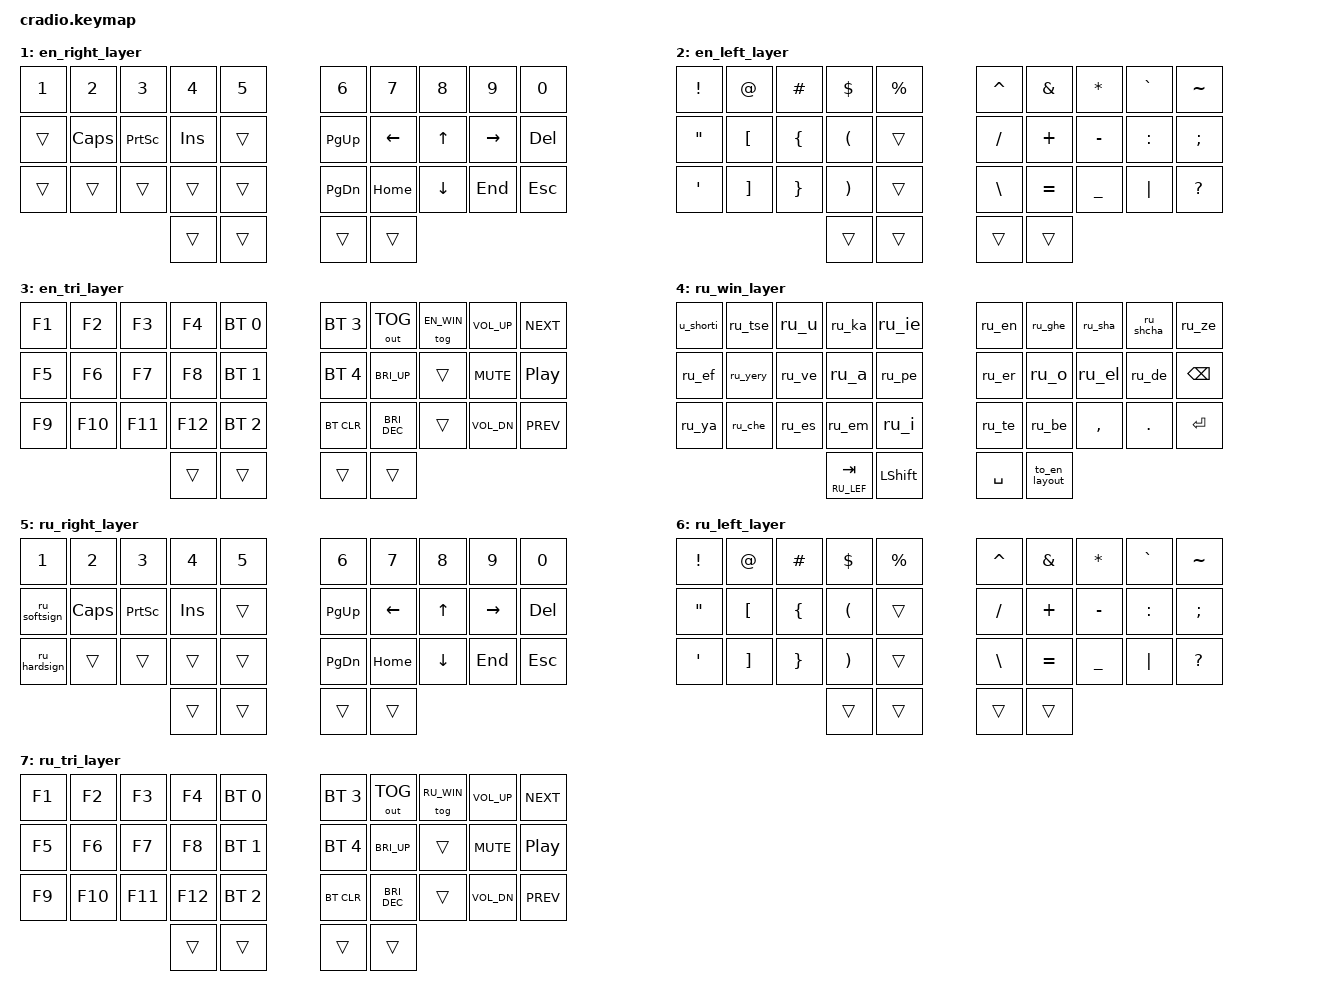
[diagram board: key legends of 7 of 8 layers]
// Copyright (c) 2022 The ZMK Contributors
// SPDX-License-Identifier: MIT

#include <behaviors.dtsi>
#include <dt-bindings/zmk/keys.h>
#include <dt-bindings/zmk/bt.h>
#include <dt-bindings/zmk/outputs.h>

// Home row mods macro
#define HRML(k2,k3,k4) &ht LALT k2  &ht LCTRL k3  &ht LGUI k4
#define HRMR(k1,k2,k3) &ht RGUI k1  &ht RCTRL k2  &ht RALT k3
#define WHRML(k2,k3,k4) &ht LALT k2  &ht LGUI k3  &ht LCTRL k4
#define WHRMR(k1,k2,k3) &ht RCTRL k1  &ht RGUI k2  &ht RALT k3

#define EN_WIN 0
#define EN_RIG 1
#define EN_LEF 2
#define EN_TRI 3
#define RU_WIN 4
#define RU_RIG 5
#define RU_LEF 6
#define RU_TRI 7

/ {
    behaviors {
        ht: hold_tap {
            label = "hold_tap";
            compatible = "zmk,behavior-hold-tap";
            #binding-cells = <2>;
            flavor = "tap-preferred";
            tapping-term-ms = <220>;
            quick-tap-ms = <150>;
            global-quick-tap;
            bindings = <&kp>, <&kp>;
        };

        // Макросы для русских букв через Alt+Unicode
        ru_shorti: ru_shorti { compatible = "zmk,behavior-macro"; label = "RU_SHORTI"; #binding-cells = <0>; 
            bindings = <&macro_press &kp LALT>, <&macro_tap &kp KP_N0 &kp KP_N4 &kp KP_N0 &kp KP_N9>, <&macro_release &kp LALT>; }; // Й
        ru_tse: ru_tse { compatible = "zmk,behavior-macro"; label = "RU_TSE"; #binding-cells = <0>; 
            bindings = <&macro_press &kp LALT>, <&macro_tap &kp KP_N0 &kp KP_N4 &kp KP_N2 &kp KP_N6>, <&macro_release &kp LALT>; }; // Ц
        ru_u: ru_u { compatible = "zmk,behavior-macro"; label = "RU_U"; #binding-cells = <0>; 
            bindings = <&macro_press &kp LALT>, <&macro_tap &kp KP_N0 &kp KP_N4 &kp KP_N2 &kp KP_N3>, <&macro_release &kp LALT>; }; // У
        ru_ka: ru_ka { compatible = "zmk,behavior-macro"; label = "RU_KA"; #binding-cells = <0>; 
            bindings = <&macro_press &kp LALT>, <&macro_tap &kp KP_N0 &kp KP_N4 &kp KP_N2 &kp KP_N0>, <&macro_release &kp LALT>; }; // К
        ru_ie: ru_ie { compatible = "zmk,behavior-macro"; label = "RU_IE"; #binding-cells = <0>; 
            bindings = <&macro_press &kp LALT>, <&macro_tap &kp KP_N0 &kp KP_N4 &kp KP_N2 &kp KP_N5>, <&macro_release &kp LALT>; }; // Е
        ru_en: ru_en { compatible = "zmk,behavior-macro"; label = "RU_EN"; #binding-cells = <0>; 
            bindings = <&macro_press &kp LALT>, <&macro_tap &kp KP_N0 &kp KP_N4 &kp KP_N2 &kp KP_N1>, <&macro_release &kp LALT>; }; // Н
        ru_ghe: ru_ghe { compatible = "zmk,behavior-macro"; label = "RU_GHE"; #binding-cells = <0>; 
            bindings = <&macro_press &kp LALT>, <&macro_tap &kp KP_N0 &kp KP_N4 &kp KP_N1 &kp KP_N7>, <&macro_release &kp LALT>; }; // Г
        ru_sha: ru_sha { compatible = "zmk,behavior-macro"; label = "RU_SHA"; #binding-cells = <0>; 
            bindings = <&macro_press &kp LALT>, <&macro_tap &kp KP_N0 &kp KP_N4 &kp KP_N2 &kp KP_N8>, <&macro_release &kp LALT>; }; // Ш
        ru_shcha: ru_shcha { compatible = "zmk,behavior-macro"; label = "RU_SHCHA"; #binding-cells = <0>; 
            bindings = <&macro_press &kp LALT>, <&macro_tap &kp KP_N0 &kp KP_N4 &kp KP_N2 &kp KP_N9>, <&macro_release &kp LALT>; }; // Щ
        ru_ze: ru_ze { compatible = "zmk,behavior-macro"; label = "RU_ZE"; #binding-cells = <0>; 
            bindings = <&macro_press &kp LALT>, <&macro_tap &kp KP_N0 &kp KP_N4 &kp KP_N1 &kp KP_N7>, <&macro_release &kp LALT>; }; // З
        ru_ha: ru_ha { compatible = "zmk,behavior-macro"; label = "RU_HA"; #binding-cells = <0>; 
            bindings = <&macro_press &kp LALT>, <&macro_tap &kp KP_N0 &kp KP_N4 &kp KP_N2 &kp KP_N5>, <&macro_release &kp LALT>; }; // Х
        ru_hardsign: ru_hardsign { compatible = "zmk,behavior-macro"; label = "RU_HARDSIGN"; #binding-cells = <0>; 
            bindings = <&macro_press &kp LALT>, <&macro_tap &kp KP_N0 &kp KP_N4 &kp KP_N2 &kp KP_N2>, <&macro_release &kp LALT>; }; // Ъ
        ru_ef: ru_ef { compatible = "zmk,behavior-macro"; label = "RU_EF"; #binding-cells = <0>; 
            bindings = <&macro_press &kp LALT>, <&macro_tap &kp KP_N0 &kp KP_N4 &kp KP_N2 &kp KP_N4>, <&macro_release &kp LALT>; }; // Ф
        ru_yery: ru_yery { compatible = "zmk,behavior-macro"; label = "RU_YERY"; #binding-cells = <0>; 
            bindings = <&macro_press &kp LALT>, <&macro_tap &kp KP_N0 &kp KP_N4 &kp KP_N2 &kp KP_N7>, <&macro_release &kp LALT>; }; // Ы
        ru_ve: ru_ve { compatible = "zmk,behavior-macro"; label = "RU_VE"; #binding-cells = <0>; 
            bindings = <&macro_press &kp LALT>, <&macro_tap &kp KP_N0 &kp KP_N4 &kp KP_N2 &kp KP_N2>, <&macro_release &kp LALT>; }; // В
        ru_a: ru_a { compatible = "zmk,behavior-macro"; label = "RU_A"; #binding-cells = <0>; 
            bindings = <&macro_press &kp LALT>, <&macro_tap &kp KP_N0 &kp KP_N4 &kp KP_N1 &kp KP_N0>, <&macro_release &kp LALT>; }; // А
        ru_pe: ru_pe { compatible = "zmk,behavior-macro"; label = "RU_PE"; #binding-cells = <0>; 
            bindings = <&macro_press &kp LALT>, <&macro_tap &kp KP_N0 &kp KP_N4 &kp KP_N1 &kp KP_N7>, <&macro_release &kp LALT>; }; // П
        ru_er: ru_er { compatible = "zmk,behavior-macro"; label = "RU_ER"; #binding-cells = <0>; 
            bindings = <&macro_press &kp LALT>, <&macro_tap &kp KP_N0 &kp KP_N4 &kp KP_N2 &kp KP_N0>, <&macro_release &kp LALT>; }; // Р
        ru_o: ru_o { compatible = "zmk,behavior-macro"; label = "RU_O"; #binding-cells = <0>; 
            bindings = <&macro_press &kp LALT>, <&macro_tap &kp KP_N0 &kp KP_N4 &kp KP_N1 &kp KP_N5>, <&macro_release &kp LALT>; }; // О
        ru_el: ru_el { compatible = "zmk,behavior-macro"; label = "RU_EL"; #binding-cells = <0>; 
            bindings = <&macro_press &kp LALT>, <&macro_tap &kp KP_N0 &kp KP_N4 &kp KP_N1 &kp KP_N2>, <&macro_release &kp LALT>; }; // Л
        ru_de: ru_de { compatible = "zmk,behavior-macro"; label = "RU_DE"; #binding-cells = <0>; 
            bindings = <&macro_press &kp LALT>, <&macro_tap &kp KP_N0 &kp KP_N4 &kp KP_N1 &kp KP_N4>, <&macro_release &kp LALT>; }; // Д
        ru_zhe: ru_zhe { compatible = "zmk,behavior-macro"; label = "RU_ZHE"; #binding-cells = <0>; 
            bindings = <&macro_press &kp LALT>, <&macro_tap &kp KP_N0 &kp KP_N4 &kp KP_N1 &kp KP_N6>, <&macro_release &kp LALT>; }; // Ж
        ru_e: ru_e { compatible = "zmk,behavior-macro"; label = "RU_E"; #binding-cells = <0>; 
            bindings = <&macro_press &kp LALT>, <&macro_tap &kp KP_N0 &kp KP_N4 &kp KP_N2 &kp KP_N3>, <&macro_release &kp LALT>; }; // Э
        ru_ya: ru_ya { compatible = "zmk,behavior-macro"; label = "RU_YA"; #binding-cells = <0>; 
            bindings = <&macro_press &kp LALT>, <&macro_tap &kp KP_N0 &kp KP_N4 &kp KP_N2 &kp KP_N7>, <&macro_release &kp LALT>; }; // Я
        ru_che: ru_che { compatible = "zmk,behavior-macro"; label = "RU_CHE"; #binding-cells = <0>; 
            bindings = <&macro_press &kp LALT>, <&macro_tap &kp KP_N0 &kp KP_N4 &kp KP_N2 &kp KP_N5>, <&macro_release &kp LALT>; }; // Ч
        ru_es: ru_es { compatible = "zmk,behavior-macro"; label = "RU_ES"; #binding-cells = <0>; 
            bindings = <&macro_press &kp LALT>, <&macro_tap &kp KP_N0 &kp KP_N4 &kp KP_N2 &kp KP_N1>, <&macro_release &kp LALT>; }; // С
        ru_em: ru_em { compatible = "zmk,behavior-macro"; label = "RU_EM"; #binding-cells = <0>; 
            bindings = <&macro_press &kp LALT>, <&macro_tap &kp KP_N0 &kp KP_N4 &kp KP_N2 &kp KP_N0>, <&macro_release &kp LALT>; }; // М
        ru_i: ru_i { compatible = "zmk,behavior-macro"; label = "RU_I"; #binding-cells = <0>; 
            bindings = <&macro_press &kp LALT>, <&macro_tap &kp KP_N0 &kp KP_N4 &kp KP_N1 &kp KP_N8>, <&macro_release &kp LALT>; }; // И
        ru_te: ru_te { compatible = "zmk,behavior-macro"; label = "RU_TE"; #binding-cells = <0>; 
            bindings = <&macro_press &kp LALT>, <&macro_tap &kp KP_N0 &kp KP_N4 &kp KP_N2 &kp KP_N2>, <&macro_release &kp LALT>; }; // Т
        ru_softsign: ru_softsign { compatible = "zmk,behavior-macro"; label = "RU_SOFTSIGN"; #binding-cells = <0>; 
            bindings = <&macro_press &kp LALT>, <&macro_tap &kp KP_N0 &kp KP_N4 &kp KP_N2 &kp KP_N6>, <&macro_release &kp LALT>; }; // Ь
        ru_be: ru_be { compatible = "zmk,behavior-macro"; label = "RU_BE"; #binding-cells = <0>; 
            bindings = <&macro_press &kp LALT>, <&macro_tap &kp KP_N0 &kp KP_N4 &kp KP_N1 &kp KP_N1>, <&macro_release &kp LALT>; }; // Б
        ru_yu: ru_yu { compatible = "zmk,behavior-macro"; label = "RU_YU"; #binding-cells = <0>; 
            bindings = <&macro_press &kp LALT>, <&macro_tap &kp KP_N0 &kp KP_N4 &kp KP_N2 &kp KP_N0>, <&macro_release &kp LALT>; }; // Ю

        // Макрос для переключения раскладки Win11 (LShift+LCtrl)
        win_ru_switch: win_ru_switch {
            compatible = "zmk,behavior-macro";
            label = "WIN_RU_SWITCH";
            #binding-cells = <0>;
            bindings = <&kp LSHIFT>, <&kp LCTRL>;
        };

        // Макрос для переключения на русскую раскладку
        to_ru_layout: to_ru_layout {
            compatible = "zmk,behavior-macro";
            label = "TO_RU_LAYOUT";
            #binding-cells = <0>;
            bindings = <
                &macro_tap &win_ru_switch
                &macro_wait_time 50
                &macro_tap &to RU_WIN
            >;
        };

        // Макрос для переключения на английскую раскладку
        to_en_layout: to_en_layout {
            compatible = "zmk,behavior-macro";
            label = "TO_EN_LAYOUT";
            #binding-cells = <0>;
            bindings = <
                &macro_tap &win_ru_switch
                &macro_wait_time 50
                &macro_tap &to EN_WIN
            >;
        };
    };

    conditional_layers {
        compatible = "zmk,conditional-layers";
        en_tri_layer {
            if-layers = <EN_RIG EN_LEF>;
            then-layer = <EN_TRI>;
        };
        ru_tri_layer {
            if-layers = <RU_RIG RU_LEF>;
            then-layer = <RU_TRI>;
        };
    };

    keymap {
        compatible = "zmk,keymap";

        // ====================================================================================================== Английская раскладка ======================================================================================================

        // ============= EN - Основной слой =============
        en_win_layer {bindings = <
        //╭─────────────────────┬─────────────────────┬─────────────────────┬─────────────────────┬─────────────────────╮   ╭─────────────────────┬─────────────────────┬─────────────────────┬─────────────────────┬─────────────────────╮
        //│          Q          │          W          │          E          │          R          │          T          │   │          Y          │          U          │          I          │          O          │          P          │
                   &ru_tse                 &kp W                 &kp E                 &kp R                 &kp T                     &kp Y                 &kp U                 &kp I                 &kp O                 &kp P
        //├─────────────────────┼─────────────────────┼─────────────────────┼─────────────────────┼─────────────────────┤   ├─────────────────────┼─────────────────────┼─────────────────────┼─────────────────────┼─────────────────────┤
        //│          A          │          S          │          D          │          F          │          G          │   │          H          │          J          │          K          │          L          │        BSPC         │
                  &kp A                                     WHRML(S, D, F)                                 &kp G                     &kp H                                    WHRMR(J, K, L)                               &kp BSPC
        //├─────────────────────┼─────────────────────┼─────────────────────┼─────────────────────┼─────────────────────┤   ├─────────────────────┼─────────────────────┼─────────────────────┼─────────────────────┼─────────────────────┤
        //│          Z          │          X          │          C          │          V          │          B          │   │          N          │          M          │         , <         │         . >         │        ENTER        │
                   &kp Z                 &kp X                 &kp C                 &kp V                 &kp B                     &kp N                 &kp M               &kp COMMA              &kp DOT              &kp ENTER
        //╰─────────────────────┴─────────────────────┴─────────────────────┼─────────────────────┼─────────────────────┤   ├─────────────────────┼─────────────────────┼─────────────────────┴─────────────────────┴─────────────────────╯
                                                                                 &lt EN_LEF TAB          &kp LSHIFT               &kp SPACE            &to_ru_layout
        //                                                                  ╰─────────────────────┴─────────────────────╯   ╰─────────────────────┴─────────────────────╯
            >;
        };

        // ============= EN - Правый слой =============
        en_right_layer {bindings = <
        //╭─────────────────────┬─────────────────────┬─────────────────────┬─────────────────────┬─────────────────────╮   ╭─────────────────────┬─────────────────────┬─────────────────────┬─────────────────────┬─────────────────────╮
        //│          1          │          2          │          3          │          4          │          5          │   │          6          │          7          │          8          │          9          │          0          │
                  &kp N1                &kp N2                &kp N3                 &kp N4               &kp N5                    &kp N6                &kp N7                &kp N8                &kp N9                &kp N0
        //├─────────────────────┼─────────────────────┼─────────────────────┼─────────────────────┼─────────────────────┤   ├─────────────────────┼─────────────────────┼─────────────────────┼─────────────────────┼─────────────────────┤
        //│                     │      CAPSLOCK       │      PRINTSCR       │       INSERT        │                     │   │      PAGE UP        │        LEFT         │         UP          │        RIGHT        │       DELETE        │
                  &trans               &kp CAPS             &kp PSCRN               &kp INS               &trans                  &kp PG_UP              &kp LEFT               &kp UP               &kp RIGHT              &kp DEL
        //├─────────────────────┼─────────────────────┼─────────────────────┼─────────────────────┼─────────────────────┤   ├─────────────────────┼─────────────────────┼─────────────────────┼─────────────────────┼─────────────────────┤
        //│                     │                     │                     │                     │                     │   │      PAGE DOWN      │        HOME         │        DOWN         │         END         │         ESC         │
                  &trans                &trans                &trans                &trans                &trans                   &kp PG_DN             &kp HOME              &kp DOWN               &kp END               &kp ESC
        //╰─────────────────────┴─────────────────────┴─────────────────────┼─────────────────────┼─────────────────────┤   ├─────────────────────┼─────────────────────┼─────────────────────┴─────────────────────┴─────────────────────╯
                                                                                      &trans               &trans                   &trans               &trans
        //                                                                  ╰─────────────────────┴─────────────────────╯   ╰─────────────────────┴─────────────────────╯
            >;
        };

        // ============= EN - Левый слой =============
        en_left_layer {bindings = <
        //╭─────────────────────┬─────────────────────┬─────────────────────┬─────────────────────┬─────────────────────╮   ╭─────────────────────┬─────────────────────┬─────────────────────┬─────────────────────┬─────────────────────╮
        //│          !          │          @          │          #          │          $          │          %          │   │          ^          │          &          │          *          │          `          │          ~          │
                 &kp EXCL               &kp AT               &kp HASH              &kp DLLR              &kp PRCNT                 &kp CARET              &kp AMPS             &kp ASTRK             &kp GRAVE             &kp TILDE
        //├─────────────────────┼─────────────────────┼─────────────────────┼─────────────────────┼─────────────────────┤   ├─────────────────────┼─────────────────────┼─────────────────────┼─────────────────────┼─────────────────────┤
        //│          "          │          [          │          {          │          (          │                     │   │          /          │          +          │          -          │          :          │          ;          │
                  &kp DQT              &kp LBKT              &kp LBRC               &kp LPAR               &trans                   &kp FSLH              &kp PLUS              &kp MINUS            &kp COLON              &kp SEMI
        //├─────────────────────┼─────────────────────┼─────────────────────┼─────────────────────┼─────────────────────┤   ├─────────────────────┼─────────────────────┼─────────────────────┼─────────────────────┼─────────────────────┤
        //│          '          │          ]          │          }          │          )          │                     │   │          \          │          =          │          _          │          |          │         ?           │
                  &kp SQT              &kp RBKT              &kp RBRC              &kp RPAR                &trans                   &kp BSLH              &kp EQUAL             &kp UNDER             &kp PIPE              &kp QMARK
        //╰─────────────────────┴─────────────────────┴─────────────────────┼─────────────────────┼─────────────────────┤   ├─────────────────────┼─────────────────────┼─────────────────────┴─────────────────────┴─────────────────────╯
                                                                                     &trans                &trans                    &trans                &trans
        //                                                                  ╰─────────────────────┴─────────────────────╯   ╰─────────────────────┴─────────────────────╯
            >;
        };

        // ============= EN - Двойной слой =============
        en_tri_layer {bindings = <
        //╭─────────────────────┬─────────────────────┬─────────────────────┬─────────────────────┬─────────────────────╮   ╭─────────────────────┬─────────────────────┬─────────────────────┬─────────────────────┬─────────────────────╮
        //│         F1          │         F2          │         F3          │         F4          │      PROFILE 0      │   │      PROFILE 3      │      TOGGLEOUT      │         WIN         │       VOL UP        │      NEXT SONG      │
                  &kp F1                &kp F2                &kp F3                &kp F4              &bt BT_SEL 0             &bt BT_SEL 3          &out OUT_TOG           &tog EN_WIN          &kp C_VOL_UP           &kp C_NEXT
        //├─────────────────────┼─────────────────────┼─────────────────────┼─────────────────────┼─────────────────────┤   ├─────────────────────┼─────────────────────┼─────────────────────┼─────────────────────┼─────────────────────┤
        //│         F5          │         F6          │         F7          │         F8          │      PROFILE 1      │   │      PROFILE 4      │     INC BRIGHT      │                     │       VOL MUTE      │     PAUSE/MUTE      │
                  &kp F5                &kp F6                &kp F7                &kp F8              &bt BT_SEL 1             &bt BT_SEL 4          &kp C_BRI_UP              &trans              &kp C_MUTE            &kp C_PP
        //├─────────────────────┼─────────────────────┼─────────────────────┼─────────────────────┼─────────────────────┤   ├─────────────────────┼─────────────────────┼─────────────────────┼─────────────────────┼─────────────────────┤
        //│         F9          │         F10         │         F11         │         F12         │      PROFILE 2      │   │      CLEAR BT       │     DEC BRIGHT      │                     │      VOL DOWN       │      PREV SONG      │
                  &kp F9                &kp F10              &kp F11                &kp F12            &bt BT_SEL 2               &bt BT_CLR           &kp C_BRI_DEC             &trans              &kp C_VOL_DN          &kp C_PREV
        //╰─────────────────────┴─────────────────────┴─────────────────────┼─────────────────────┼─────────────────────┤   ├─────────────────────┼─────────────────────┼─────────────────────┴─────────────────────┴─────────────────────╯
                                                                                     &trans               &trans                     &trans                &trans
        //                                                                  ╰─────────────────────┴─────────────────────╯   ╰─────────────────────┴─────────────────────╯
            >;
        };



        // ======================================================================================================= Русская раскладка =======================================================================================================
        // ============= RU - Основной слой =============
        ru_win_layer {bindings = <
        //╭─────────────────────┬─────────────────────┬─────────────────────┬─────────────────────┬─────────────────────╮   ╭─────────────────────┬─────────────────────┬─────────────────────┬─────────────────────┬─────────────────────╮
        //│          Й          │          Ц          │          У          │          К          │          Е          │   │          Н          │          Г          │          Ш          │          Щ          │          З          │
                  u_shorti              &ru_tse                &ru_u                &ru_ka                 &ru_ie                   &ru_en               &ru_ghe                &ru_sha              &ru_shcha              &ru_ze
        //├─────────────────────┼─────────────────────┼─────────────────────┼─────────────────────┼─────────────────────┤   ├─────────────────────┼─────────────────────┼─────────────────────┼─────────────────────┼─────────────────────┤
        //│          Ф          │          Ы          │          В          │          А          │          П          │   │          Р          │          О          │          Л          │          Д          │        BSPC         │
                   &ru_ef              &ru_yery               &ru_ve                 &ru_a                &ru_pe                    &ru_er                 &ru_o                &ru_el              &ru_de                &kp BSPC
        //├─────────────────────┼─────────────────────┼─────────────────────┼─────────────────────┼─────────────────────┤   ├─────────────────────┼─────────────────────┼─────────────────────┼─────────────────────┼─────────────────────┤
        //│          Я          │          Ч          │          С          │          М          │          И          │   │          Т          │          Б          │         , <         │         . >         │        ENTER        │
                   &ru_ya              &ru_che                &ru_es                &ru_em                 &ru_i                    &ru_te               &ru_be               &kp COMMA            &kp DOT               &kp ENTER
        //╰─────────────────────┴─────────────────────┴─────────────────────┼─────────────────────┼─────────────────────┤   ├─────────────────────┼─────────────────────┼─────────────────────┴─────────────────────┴─────────────────────╯
                                                                                 &lt RU_LEF TAB          &kp LSHIFT               &kp SPACE            &to_en_layout
        //                                                                  ╰─────────────────────┴─────────────────────╯   ╰─────────────────────┴─────────────────────╯
            >;
        };

        // ============= RU - Правый слой =============
        ru_right_layer {bindings = <
        //╭─────────────────────┬─────────────────────┬─────────────────────┬─────────────────────┬─────────────────────╮   ╭─────────────────────┬─────────────────────┬─────────────────────┬─────────────────────┬─────────────────────╮
        //│          1          │          2          │          3          │          4          │          5          │   │          6          │          7          │          8          │          9          │          0          │
                  &kp N1                &kp N2                &kp N3                &kp N4                &kp N5                    &kp N6                &kp N7                &kp N8                &kp N9                 &kp N0
        //├─────────────────────┼─────────────────────┼─────────────────────┼─────────────────────┼─────────────────────┤   ├─────────────────────┼─────────────────────┼─────────────────────┼─────────────────────┼─────────────────────┤
        //│          Ь          │       CAPSLOCK      │      PRINTSCR       │        INSERT       │                     │   │      PAGE UP        │        LEFT         │         UP          │        RIGHT        │       DELETE        │
              &ru_softsign             &kp CAPS             &kp PSCRN              &kp INS               &trans                  &kp PG_UP              &kp LEFT               &kp UP               &kp RIGHT              &kp DEL
        //├─────────────────────┼─────────────────────┼─────────────────────┼─────────────────────┼─────────────────────┤   ├─────────────────────┼─────────────────────┼─────────────────────┼─────────────────────┼─────────────────────┤
        //│          Ъ          │                     │                     │                     │                     │   │      PAGE DOWN      │         HOME        │        DOWN         │         END         │         ESC         │
              &ru_hardsign              &trans                &trans                 &trans               &trans                  &kp PG_DN              &kp HOME             &kp DOWN               &kp END               &kp ESC
        //╰─────────────────────┴─────────────────────┴─────────────────────┼─────────────────────┼─────────────────────┤   ├─────────────────────┼─────────────────────┼─────────────────────┴─────────────────────┴─────────────────────╯
                                                                                     &trans               &trans                     &trans               &trans
        //                                                                  ╰─────────────────────┴─────────────────────╯   ╰─────────────────────┴─────────────────────╯
            >;
        };

        // ============= RU - Левый слой =============
        ru_left_layer {bindings = <
        //╭─────────────────────┬─────────────────────┬─────────────────────┬─────────────────────┬─────────────────────╮   ╭─────────────────────┬─────────────────────┬─────────────────────┬─────────────────────┬─────────────────────╮
        //│          !          │          @          │          #          │          $          │          %          │   │          ^          │          &          │          *          │          `          │          ~          │
                  &kp EXCL               &kp AT               &kp HASH             &kp DLLR              &kp PRCNT                 &kp CARET              &kp AMPS             &kp ASTRK             &kp GRAVE             &kp TILDE
        //├─────────────────────┼─────────────────────┼─────────────────────┼─────────────────────┼─────────────────────┤   ├─────────────────────┼─────────────────────┼─────────────────────┼─────────────────────┼─────────────────────┤
        //│          "          │          [          │          {          │          (          │                     │   │          /          │          +          │          -          │          :          │          ;          │
                  &kp DQT               &kp LBKT              &kp LBRC             &kp LPAR                &trans                   &kp FSLH              &kp PLUS             &kp MINUS             &kp COLON             &kp SEMI
        //├─────────────────────┼─────────────────────┼─────────────────────┼─────────────────────┼─────────────────────┤   ├─────────────────────┼─────────────────────┼─────────────────────┼─────────────────────┼─────────────────────┤
        //│          '          │          ]          │          }          │          )          │                     │   │          \          │          =          │          _          │          |          │          ?          │
                  &kp SQT               &kp RBKT              &kp RBRC             &kp RPAR                &trans                   &kp BSLH              &kp EQUAL            &kp UNDER              &kp PIPE             &kp QMARK
        //╰─────────────────────┴─────────────────────┴─────────────────────┼─────────────────────┼─────────────────────┤   ├─────────────────────┼─────────────────────┼─────────────────────┴─────────────────────┴─────────────────────╯
                                                                                     &trans                &trans                    &trans                &trans
        //                                                                  ╰─────────────────────┴─────────────────────╯   ╰─────────────────────┴─────────────────────╯
            >;
        };

        // ============= RU - Двойной слой =============
        ru_tri_layer {bindings = <
        //╭─────────────────────┬─────────────────────┬─────────────────────┬─────────────────────┬─────────────────────╮   ╭─────────────────────┬─────────────────────┬─────────────────────┬─────────────────────┬─────────────────────╮
        //│         F1          │         F2          │         F3          │         F4          │      PROFILE 0      │   │      PROFILE 3      │      TOGGLEOUT      │         WIN         │       VOL UP        │      NEXT SONG      │
                  &kp F1                &kp F2                &kp F3                &kp F4             &bt BT_SEL 0              &bt BT_SEL 3           &out OUT_TOG          &tog RU_WIN          &kp C_VOL_UP          &kp C_NEXT
        //├─────────────────────┼─────────────────────┼─────────────────────┼─────────────────────┼─────────────────────┤   ├─────────────────────┼─────────────────────┼─────────────────────┼─────────────────────┼─────────────────────┤
        //│         F5          │         F6          │         F7          │         F8          │      PROFILE 1      │   │      PROFILE 4      │      INC BRIGHT     │                     │       VOL MUTE      │     PAUSE/MUTE      │
                  &kp F5                &kp F6                &kp F7                &kp F8             &bt BT_SEL 1              &bt BT_SEL 4           &kp C_BRI_UP             &trans              &kp C_MUTE            &kp C_PP
        //├─────────────────────┼─────────────────────┼─────────────────────┼─────────────────────┼─────────────────────┤   ├─────────────────────┼─────────────────────┼─────────────────────┼─────────────────────┼─────────────────────┤
        //│         F9          │         F10         │         F11         │         F12         │      PROFILE 2      │   │      CLEAR BT       │      DEC BRIGHT     │                     │      VOL DOWN       │      PREV SONG      │
                  &kp F9                &kp F10               &kp F11               &kp F12            &bt BT_SEL 2               &bt BT_CLR           &kp C_BRI_DEC             &trans            &kp C_VOL_DN            &kp C_PREV
        //╰─────────────────────┴─────────────────────┴─────────────────────┼─────────────────────┼─────────────────────┤   ├─────────────────────┼─────────────────────┼─────────────────────┴─────────────────────┴─────────────────────╯
                                                                                     &trans               &trans                     &trans               &trans
        //                                                                  ╰─────────────────────┴─────────────────────╯   ╰─────────────────────┴─────────────────────╯
            >;
        };
    };
};
